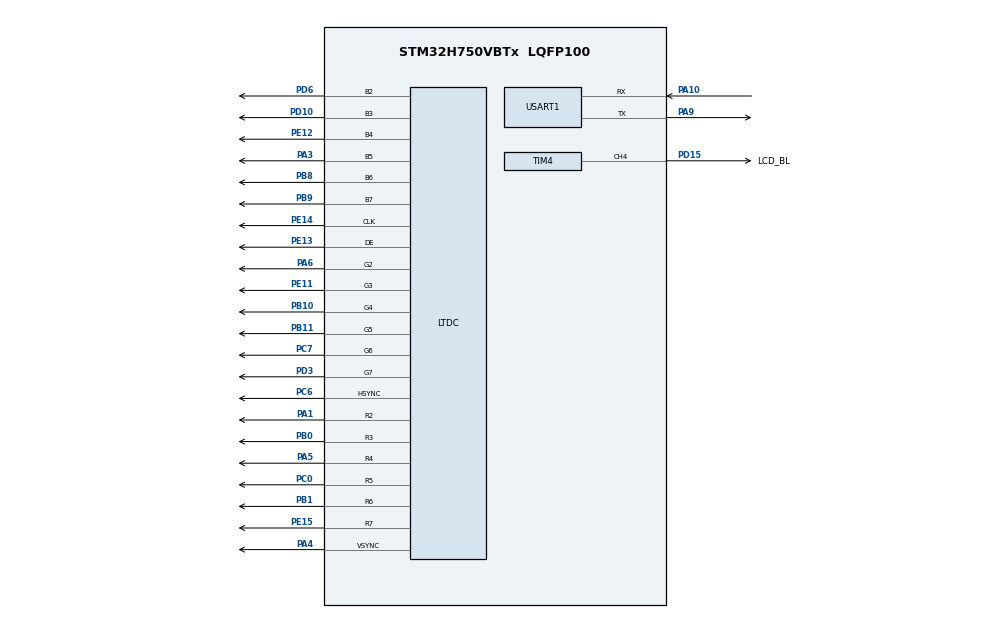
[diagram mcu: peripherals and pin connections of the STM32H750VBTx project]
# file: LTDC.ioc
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CORTEX_M7.default_mode_Activation=1
DMA2D.ColorMode=DMA2D_OUTPUT_RGB565
LTDC.ActiveH=272
LTDC.ActiveW=480
LTDC.BlendingFactor1_L0=LTDC_BLENDING_FACTOR1_PAxCA
LTDC.BlendingFactor1_L1=LTDC_BLENDING_FACTOR1_PAxCA
LTDC.BlendingFactor2_L0=LTDC_BLENDING_FACTOR2_PAxCA
LTDC.BlendingFactor2_L1=LTDC_BLENDING_FACTOR2_PAxCA
LTDC.Blue=255
LTDC.Blue_L0=255
LTDC.FBStartAdress_L0=LAYER0_ADDR
LTDC.FBStartAdress_L1=LAYER1_ADDR
LTDC.Green=255
LTDC.Green_L0=255
LTDC.HBP=43
LTDC.HFP=75
LTDC.HSync=1
LTDC.ImageHeight_L0=LCD_HEIGHT
LTDC.ImageHeight_L1=LCD_HEIGHT
LTDC.ImageWidth_L0=LCD_WIDTH
LTDC.Layers=0
LTDC.PixelFormat_L0=LTDC_PIXEL_FORMAT_RGB565
LTDC.Red=255
LTDC.Red_L0=255
LTDC.VBP=12
LTDC.VFP=37
LTDC.VSync=1
LTDC.WindowX1_L0=480
LTDC.WindowX1_L1=480
LTDC.WindowY1_L0=272
LTDC.WindowY1_L1=272
Mcu.Family=STM32H7
Mcu.Name=STM32H750VBTx
Mcu.Package=LQFP100
Mcu.UserConstants=LAYER0_ADDR,0X24000000;LCD_WIDTH,480;LCD_HEIGHT,272
NVIC.DMA2D_IRQn=true\:0\:0\:false\:false\:true\:true\:true\:true
NVIC.LTDC_IRQn=true\:0\:0\:false\:false\:true\:true\:true\:true
NVIC.PriorityGroup=NVIC_PRIORITYGROUP_4
PA1.GPIO_Speed=GPIO_SPEED_FREQ_VERY_HIGH
PA1.Mode=RGB666
PA1.Signal=LTDC_R2
PA10.Mode=Asynchronous
PA10.Signal=USART1_RX
PA13\ (JTMS/SWDIO).Mode=Serial_Wire
PA13\ (JTMS/SWDIO).Signal=DEBUG_JTMS-SWDIO
PA14\ (JTCK/SWCLK).Mode=Serial_Wire
PA14\ (JTCK/SWCLK).Signal=DEBUG_JTCK-SWCLK
PA3.GPIO_Speed=GPIO_SPEED_FREQ_VERY_HIGH
PA3.Mode=RGB666
PA3.Signal=LTDC_B5
PA4.GPIO_Speed=GPIO_SPEED_FREQ_VERY_HIGH
PA4.Mode=RGB666
PA4.Signal=LTDC_VSYNC
PA5.GPIO_Speed=GPIO_SPEED_FREQ_VERY_HIGH
PA5.Mode=RGB666
PA5.Signal=LTDC_R4
PA6.GPIO_Speed=GPIO_SPEED_FREQ_VERY_HIGH
PA6.Mode=RGB666
PA6.Signal=LTDC_G2
PA9.Mode=Asynchronous
PA9.Signal=USART1_TX
PB0.GPIO_Speed=GPIO_SPEED_FREQ_VERY_HIGH
PB0.Mode=RGB666
PB0.Signal=LTDC_R3
PB1.GPIO_Speed=GPIO_SPEED_FREQ_VERY_HIGH
PB1.Mode=RGB666
PB1.Signal=LTDC_R6
PB10.GPIO_Speed=GPIO_SPEED_FREQ_VERY_HIGH
PB10.Mode=RGB666
PB10.Signal=LTDC_G4
PB11.GPIO_Speed=GPIO_SPEED_FREQ_VERY_HIGH
PB11.Mode=RGB666
PB11.Signal=LTDC_G5
PB8.GPIO_Speed=GPIO_SPEED_FREQ_VERY_HIGH
PB8.Mode=RGB666
PB8.Signal=LTDC_B6
PB9.GPIO_Speed=GPIO_SPEED_FREQ_VERY_HIGH
PB9.Mode=RGB666
PB9.Signal=LTDC_B7
PC0.GPIO_Speed=GPIO_SPEED_FREQ_VERY_HIGH
PC0.Mode=RGB666
PC0.Signal=LTDC_R5
PC14-OSC32_IN\ (OSC32_IN).Mode=LSE-External-Oscillator
PC14-OSC32_IN\ (OSC32_IN).Signal=RCC_OSC32_IN
PC15-OSC32_OUT\ (OSC32_OUT).Mode=LSE-External-Oscillator
PC15-OSC32_OUT\ (OSC32_OUT).Signal=RCC_OSC32_OUT
PC6.GPIO_Speed=GPIO_SPEED_FREQ_VERY_HIGH
PC6.Mode=RGB666
PC6.Signal=LTDC_HSYNC
PC7.GPIO_Speed=GPIO_SPEED_FREQ_VERY_HIGH
PC7.Mode=RGB666
PC7.Signal=LTDC_G6
PD10.GPIO_Speed=GPIO_SPEED_FREQ_VERY_HIGH
PD10.Mode=RGB666
PD10.Signal=LTDC_B3
PD15.GPIO_Label=LCD_BL
PD15.Signal=S_TIM4_CH4
PD3.GPIO_Speed=GPIO_SPEED_FREQ_VERY_HIGH
PD3.Mode=RGB666
PD3.Signal=LTDC_G7
PD6.GPIO_Speed=GPIO_SPEED_FREQ_VERY_HIGH
PD6.Mode=RGB666
PD6.Signal=LTDC_B2
PE11.GPIO_Speed=GPIO_SPEED_FREQ_VERY_HIGH
PE11.Mode=RGB666
PE11.Signal=LTDC_G3
PE12.GPIO_Speed=GPIO_SPEED_FREQ_VERY_HIGH
PE12.Mode=RGB666
PE12.Signal=LTDC_B4
PE13.GPIO_Speed=GPIO_SPEED_FREQ_VERY_HIGH
PE13.Mode=RGB666
PE13.Signal=LTDC_DE
PE14.GPIO_Speed=GPIO_SPEED_FREQ_VERY_HIGH
PE14.Mode=RGB666
PE14.Signal=LTDC_CLK
PE15.GPIO_Speed=GPIO_SPEED_FREQ_VERY_HIGH
PE15.Mode=RGB666
PE15.Signal=LTDC_R7
PH0-OSC_IN\ (PH0).Mode=HSE-External-Oscillator
PH0-OSC_IN\ (PH0).Signal=RCC_OSC_IN
PH1-OSC_OUT\ (PH1).Mode=HSE-External-Oscillator
PH1-OSC_OUT\ (PH1).Signal=RCC_OSC_OUT
ProjectManager.HeapSize=0x1000
ProjectManager.StackSize=0x1000
ProjectManager.TargetToolchain=SW4STM32
RCC.ADCFreq_Value=120000000
RCC.APB1Freq_Value=100000000
RCC.APB2Freq_Value=100000000
RCC.APB3Freq_Value=100000000
RCC.APB4Freq_Value=100000000
RCC.CortexFreq_Value=400000000
RCC.D1PPRE=RCC_APB3_DIV2
RCC.D2PPRE1=RCC_APB1_DIV2
RCC.D2PPRE2=RCC_APB2_DIV2
RCC.D3PPRE=RCC_APB4_DIV2
RCC.DIVM1=2
RCC.DIVM2=5
RCC.DIVM3=1
RCC.DIVN1=64
RCC.DIVN2=48
RCC.DIVN3=12
RCC.DIVR2=5
RCC.DIVR3=25
RCC.HCLKFreq_Value=200000000
RCC.HPRE=RCC_HCLK_DIV2
RCC.PLL2FRACN=0
RCC.PLL3FRACN=0
RCC.PLLFRACN=0
RCC.PLLSourceVirtual=RCC_PLLSOURCE_HSE
RCC.PWR_Regulator_Voltage_Scale=PWR_REGULATOR_VOLTAGE_SCALE1
RCC.SDMMC1CLockSelection=RCC_SDMMCCLKSOURCE_PLL2
RCC.SYSCLKFreq_VALUE=400000000
RCC.SYSCLKSource=RCC_SYSCLKSOURCE_PLLCLK
RCC.USBFreq_Value=400000000
SH.S_TIM4_CH4.0=TIM4_CH4,PWM Generation4 CH4
TIM4.AutoReloadPreload=TIM_AUTORELOAD_PRELOAD_ENABLE
TIM4.Channel-PWM\ Generation4\ CH4=TIM_CHANNEL_4
TIM4.Period=1000
TIM4.Prescaler=10
USART1.VirtualMode-Asynchronous=VM_ASYNC
VP_DMA2D_VS_DMA2D.Mode=DMA2D_Activate
VP_TIM4_VS_ClockSourceINT.Mode=Internal
board=custom

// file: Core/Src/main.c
/* USER CODE BEGIN Header */
/**
  ******************************************************************************
  * @file           : main.c
  * @brief          : Main program body
  ******************************************************************************
  * @attention
  *
  * Copyright (c) 2022 STMicroelectronics.
  * All rights reserved.
  *
  * This software is licensed under terms that can be found in the LICENSE file
  * in the root directory of this software component.
  * If no LICENSE file comes with this software, it is provided AS-IS.
  *
  ******************************************************************************
  */
/* USER CODE END Header */
#include "main.h"
#include "dma2d.h"
#include "ltdc.h"
#include "tim.h"
#include "usart.h"
#include "gpio.h"

/* USER CODE BEGIN Includes */
#include "touch_480x272.h"

/* USER CODE END Includes */

void SystemClock_Config(void);
static void MPU_Config(void);

/* USER CODE BEGIN 0 */
static uint16_t LCD_BUFFER[272][480] __attribute__((section(".ram_d1")));
/* USER CODE END 0 */

int main(void)
{

  /* MPU Configuration--------------------------------------------------------*/
  MPU_Config();

  /* MCU Configuration--------------------------------------------------------*/

  /* Reset of all peripherals, Initializes the Flash interface and the Systick. */
  HAL_Init();

  /* Configure the system clock */
  SystemClock_Config();

  /* USER CODE BEGIN SysInit */
//  HAL_MPU_Disable();
  /* USER CODE END SysInit */

  /* Initialize all configured peripherals */
  MX_GPIO_Init();
  MX_USART1_UART_Init();
  MX_LTDC_Init();
  MX_TIM4_Init();
  MX_DMA2D_Init();
  /* USER CODE BEGIN 2 */

    Touch_Init();

    printf("Init ok~\r\n");
    HAL_TIM_PWM_Start(&htim4,TIM_CHANNEL_4);
    __HAL_TIM_SET_COMPARE(&htim4,TIM_CHANNEL_4,1000);

  /* USER CODE END 2 */

  /* Infinite loop */
  /* USER CODE BEGIN WHILE */

  while (1)
  {
/*      memset(LCD_BUFFER,0xFF,sizeof(LCD_BUFFER));
      HAL_Delay(100);
      memset(LCD_BUFFER,0xAA,sizeof(LCD_BUFFER));
      HAL_Delay(100);
      memset(LCD_BUFFER,0xDD,sizeof(LCD_BUFFER));
      HAL_Delay(100);
      memset(LCD_BUFFER,0xCC,sizeof(LCD_BUFFER));
      HAL_Delay(100);*/
    Touch_Scan();
      if(touchInfo.flag == 1)
      {
          printf("X=%i16u,Y=%i16u\r\n",touchInfo.x[0],touchInfo.y[0]);
      }
      HAL_Delay(20);
    /* USER CODE END WHILE */

  }
}

void SystemClock_Config(void)
{
  RCC_OscInitTypeDef RCC_OscInitStruct = {0};
  RCC_ClkInitTypeDef RCC_ClkInitStruct = {0};

  /** Supply configuration update enable
  */
  HAL_PWREx_ConfigSupply(PWR_LDO_SUPPLY);

  /** Configure the main internal regulator output voltage
  */
  __HAL_PWR_VOLTAGESCALING_CONFIG(PWR_REGULATOR_VOLTAGE_SCALE1);

  while(!__HAL_PWR_GET_FLAG(PWR_FLAG_VOSRDY)) {}

  /** Macro to configure the PLL clock source
  */
  __HAL_RCC_PLL_PLLSOURCE_CONFIG(RCC_PLLSOURCE_HSE);

  /** Initializes the RCC Oscillators according to the specified parameters
  * in the RCC_OscInitTypeDef structure.
  */
  RCC_OscInitStruct.OscillatorType = RCC_OSCILLATORTYPE_HSE;
  RCC_OscInitStruct.HSEState = RCC_HSE_ON;
  RCC_OscInitStruct.PLL.PLLState = RCC_PLL_ON;
  RCC_OscInitStruct.PLL.PLLSource = RCC_PLLSOURCE_HSE;
  RCC_OscInitStruct.PLL.PLLM = 2;
  RCC_OscInitStruct.PLL.PLLN = 64;
  RCC_OscInitStruct.PLL.PLLP = 2;
  RCC_OscInitStruct.PLL.PLLQ = 2;
  RCC_OscInitStruct.PLL.PLLR = 2;
  RCC_OscInitStruct.PLL.PLLRGE = RCC_PLL1VCIRANGE_3;
  RCC_OscInitStruct.PLL.PLLVCOSEL = RCC_PLL1VCOWIDE;
  RCC_OscInitStruct.PLL.PLLFRACN = 0;
  if (HAL_RCC_OscConfig(&RCC_OscInitStruct) != HAL_OK)
  {
    Error_Handler();
  }

  /** Initializes the CPU, AHB and APB buses clocks
  */
  RCC_ClkInitStruct.ClockType = RCC_CLOCKTYPE_HCLK|RCC_CLOCKTYPE_SYSCLK
                              |RCC_CLOCKTYPE_PCLK1|RCC_CLOCKTYPE_PCLK2
                              |RCC_CLOCKTYPE_D3PCLK1|RCC_CLOCKTYPE_D1PCLK1;
  RCC_ClkInitStruct.SYSCLKSource = RCC_SYSCLKSOURCE_PLLCLK;
  RCC_ClkInitStruct.SYSCLKDivider = RCC_SYSCLK_DIV1;
  RCC_ClkInitStruct.AHBCLKDivider = RCC_HCLK_DIV2;
  RCC_ClkInitStruct.APB3CLKDivider = RCC_APB3_DIV2;
  RCC_ClkInitStruct.APB1CLKDivider = RCC_APB1_DIV2;
  RCC_ClkInitStruct.APB2CLKDivider = RCC_APB2_DIV2;
  RCC_ClkInitStruct.APB4CLKDivider = RCC_APB4_DIV2;

  if (HAL_RCC_ClockConfig(&RCC_ClkInitStruct, FLASH_LATENCY_2) != HAL_OK)
  {
    Error_Handler();
  }
}

/* MPU Configuration */

void MPU_Config(void)
{
  MPU_Region_InitTypeDef MPU_InitStruct = {0};

  /* Disables the MPU */
  HAL_MPU_Disable();

  /** Initializes and configures the Region and the memory to be protected
  */
  MPU_InitStruct.Enable = MPU_REGION_ENABLE;
  MPU_InitStruct.Number = MPU_REGION_NUMBER0;
  MPU_InitStruct.BaseAddress = 0x0;
  MPU_InitStruct.Size = MPU_REGION_SIZE_4GB;
  MPU_InitStruct.SubRegionDisable = 0x87;
  MPU_InitStruct.TypeExtField = MPU_TEX_LEVEL0;
  MPU_InitStruct.AccessPermission = MPU_REGION_NO_ACCESS;
  MPU_InitStruct.DisableExec = MPU_INSTRUCTION_ACCESS_DISABLE;
  MPU_InitStruct.IsShareable = MPU_ACCESS_SHAREABLE;
  MPU_InitStruct.IsCacheable = MPU_ACCESS_NOT_CACHEABLE;
  MPU_InitStruct.IsBufferable = MPU_ACCESS_NOT_BUFFERABLE;

  HAL_MPU_ConfigRegion(&MPU_InitStruct);
  /* Enables the MPU */
  HAL_MPU_Enable(MPU_PRIVILEGED_DEFAULT);

}

void Error_Handler(void)
{
  __disable_irq();
  while (1)
  {
  }
}
